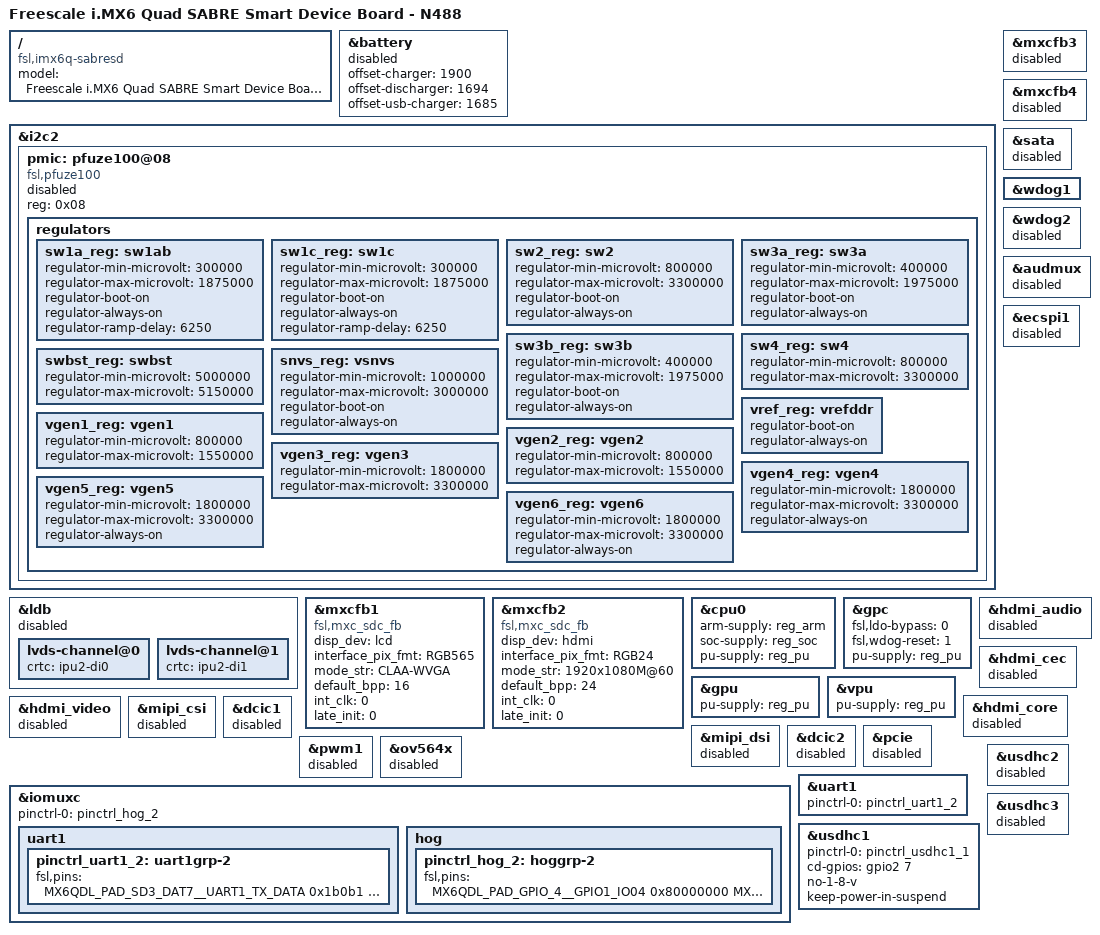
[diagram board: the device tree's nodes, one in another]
/*
 * Copyright 2012 Freescale Semiconductor, Inc.
 * Copyright 2011 Linaro Ltd.
 *
 * The code contained herein is licensed under the GNU General Public
 * License. You may obtain a copy of the GNU General Public License
 * Version 2 or later at the following locations:
 *
 * http://www.opensource.org/licenses/gpl-license.html
 * http://www.gnu.org/copyleft/gpl.html
 */

/dts-v1/;

#include "imx6q.dtsi"
#include "imx6qdl-sabresd.dtsi"

/ {
	model = "Freescale i.MX6 Quad SABRE Smart Device Board - N488";
	compatible = "fsl,imx6q-sabresd", "fsl,imx6q";
};

&battery {
	status = "disabled";
	offset-charger = <1900>;
	offset-discharger = <1694>;
	offset-usb-charger = <1685>;
};

&i2c2 {
	pmic: pfuze100@08 {
		status = "disabled";
		compatible = "fsl,pfuze100";
		reg = <0x08>;

		regulators {
			sw1a_reg: sw1ab {
				regulator-min-microvolt = <300000>;
				regulator-max-microvolt = <1875000>;
				regulator-boot-on;
				regulator-always-on;
				regulator-ramp-delay = <6250>;
			};

			sw1c_reg: sw1c {
				regulator-min-microvolt = <300000>;
				regulator-max-microvolt = <1875000>;
				regulator-boot-on;
				regulator-always-on;
				regulator-ramp-delay = <6250>;
			};

			sw2_reg: sw2 {
				regulator-min-microvolt = <800000>;
				regulator-max-microvolt = <3300000>;
				regulator-boot-on;
				regulator-always-on;
			};

			sw3a_reg: sw3a {
				regulator-min-microvolt = <400000>;
				regulator-max-microvolt = <1975000>;
				regulator-boot-on;
				regulator-always-on;
			};

			sw3b_reg: sw3b {
				regulator-min-microvolt = <400000>;
				regulator-max-microvolt = <1975000>;
				regulator-boot-on;
				regulator-always-on;
			};

			sw4_reg: sw4 {
				regulator-min-microvolt = <800000>;
				regulator-max-microvolt = <3300000>;
			};

			swbst_reg: swbst {
				regulator-min-microvolt = <5000000>;
				regulator-max-microvolt = <5150000>;
			};

			snvs_reg: vsnvs {
				regulator-min-microvolt = <1000000>;
				regulator-max-microvolt = <3000000>;
				regulator-boot-on;
				regulator-always-on;
			};

			vref_reg: vrefddr {
				regulator-boot-on;
				regulator-always-on;
			};

			vgen1_reg: vgen1 {
				regulator-min-microvolt = <800000>;
				regulator-max-microvolt = <1550000>;
			};

			vgen2_reg: vgen2 {
				regulator-min-microvolt = <800000>;
				regulator-max-microvolt = <1550000>;
			};

			vgen3_reg: vgen3 {
				regulator-min-microvolt = <1800000>;
				regulator-max-microvolt = <3300000>;
			};

			vgen4_reg: vgen4 {
				regulator-min-microvolt = <1800000>;
				regulator-max-microvolt = <3300000>;
				regulator-always-on;
			};

			vgen5_reg: vgen5 {
				regulator-min-microvolt = <1800000>;
				regulator-max-microvolt = <3300000>;
				regulator-always-on;
			};

			vgen6_reg: vgen6 {
				regulator-min-microvolt = <1800000>;
				regulator-max-microvolt = <3300000>;
				regulator-always-on;
			};
		};
	};
};

&ldb {
	status = "disabled";
	lvds-channel@0 {
		crtc = "ipu2-di0";
	};

	lvds-channel@1 {
		crtc = "ipu2-di1";
	};
};

/* use lcd panel as fb1 out */
&mxcfb1 {
	compatible = "fsl,mxc_sdc_fb";
	disp_dev = "lcd";
	interface_pix_fmt = "RGB565";
	mode_str ="CLAA-WVGA";
	default_bpp = <16>;
	int_clk = <0>;
	late_init = <0>;
	status = "okay";
};

/* use hdmi as fb2 out */
&mxcfb2 {
	compatible = "fsl,mxc_sdc_fb";
	disp_dev = "hdmi";
	interface_pix_fmt = "RGB24";
	mode_str ="1920x1080M@60";
	default_bpp = <24>;
	int_clk = <0>;
	late_init = <0>;
	status = "okay";
};

/* disable fb3 for now */
&mxcfb3 {
	status = "disabled";
};

/* disable fb4 for now */
&mxcfb4 {
	status = "disabled";
};

/* disable sata for now */
&sata {
	status = "disabled";
};



&cpu0 {
	arm-supply = <&reg_arm>;
	soc-supply = <&reg_soc>;
	pu-supply = <&reg_pu>; /* use pu_dummy if VDDSOC share with VDDPU */
};

&gpc {
	fsl,ldo-bypass = <0>; /* use ldo-bypass, u-boot will check it and configure */
	fsl,wdog-reset = <1>; /* watchdog select of reset source */
	pu-supply = <&reg_pu>; /* ldo-bypass:use pu_dummy if VDDSOC share with VDDPU */
};

&gpu {
	pu-supply = <&reg_pu>; /* ldo-bypass:use pu_dummy if VDDSOC share with VDDPU */
};

&vpu {
	pu-supply = <&reg_pu>; /* ldo-bypass:use pu_dummy if VDDSOC share with VDDPU */
};

&wdog1 {
	status = "okay";
};

&wdog2 {
	status = "disabled";
};


/*
 * modify for n488. +++
 */

/*
&backlight {
	status = "disabled";
};

&gpio-keys {
	status = "disabled";
};

&leds {
	status = "disabled";
};

&sound-hdmi {
	status = "disabled";
};

&sound {
	status = "disabled";
};
*/

&audmux {
	status = "disabled";
};

&ecspi1 {
	status = "disabled";
};

&hdmi_audio {
	status = "disabled";
};

&hdmi_cec {
	status = "disabled";
};

&hdmi_core {
	status = "disabled";
};

&hdmi_video {
	status = "disabled";
};

&mipi_csi {
	status = "disabled";
};

&mipi_dsi {
	status = "disabled";
};

&dcic1 {
	status = "disabled";
};

&dcic2 {
	status = "disabled";
};

&pcie {
	status = "disabled";
};

&pwm1 {
	status = "disabled";
};

&ov564x {
	status = "disabled";
};

&iomuxc {
	uart1 {
		pinctrl_uart1_2: uart1grp-2 {
			fsl,pins = <
				MX6QDL_PAD_SD3_DAT7__UART1_TX_DATA 0x1b0b1
				MX6QDL_PAD_SD3_DAT6__UART1_RX_DATA 0x1b0b1
			>;
		};
	};
};

&uart1 {
	pinctrl-names = "default";
	pinctrl-0 = <&pinctrl_uart1_2>;
	status = "okay";
};

&iomuxc {
	pinctrl-names = "default";
	pinctrl-0 = <&pinctrl_hog_2>;

	hog {
		pinctrl_hog_2: hoggrp-2 {
			fsl,pins = <
				MX6QDL_PAD_GPIO_4__GPIO1_IO04   0x80000000
				MX6QDL_PAD_GPIO_5__GPIO1_IO05   0x80000000
				MX6QDL_PAD_NANDF_D0__GPIO2_IO00 0x80000000
				MX6QDL_PAD_NANDF_D1__GPIO2_IO01 0x80000000
				MX6QDL_PAD_NANDF_D2__GPIO2_IO02 0x80000000
				MX6QDL_PAD_NANDF_D3__GPIO2_IO03 0x80000000
				MX6QDL_PAD_NANDF_ALE__GPIO6_IO08 0x80000000
				MX6QDL_PAD_NANDF_CLE__GPIO6_IO07 0x80000000
				MX6QDL_PAD_GPIO_0__CCM_CLKO1    0x130b0
				MX6QDL_PAD_NANDF_CS2__GPIO6_IO15 0x80000000
				MX6QDL_PAD_NANDF_CS3__GPIO6_IO16 0x80000000
				MX6QDL_PAD_EIM_D26__GPIO3_IO26 0x80000000
				MX6QDL_PAD_EIM_CS1__GPIO2_IO24 0x80000000
				MX6QDL_PAD_ENET_RXD0__GPIO1_IO27 0x80000000
				MX6QDL_PAD_EIM_A25__GPIO5_IO02 0x80000000
				MX6QDL_PAD_EIM_D23__GPIO3_IO23 0x80000000
				MX6QDL_PAD_ENET_TXD1__GPIO1_IO29 0x80000000
				MX6QDL_PAD_EIM_D22__GPIO3_IO22  0x80000000
				MX6QDL_PAD_NANDF_CS0__GPIO6_IO11 0x80000000
				MX6QDL_PAD_NANDF_CS1__GPIO6_IO14 0x80000000
				MX6QDL_PAD_EIM_EB3__GPIO2_IO31 0x80000000
				MX6QDL_PAD_EIM_D16__GPIO3_IO16 0x80000000
				MX6QDL_PAD_EIM_DA9__GPIO3_IO09 0x80000000
				MX6QDL_PAD_GPIO_4__GPIO1_IO04 0x80000000
				MX6QDL_PAD_GPIO_5__GPIO1_IO05 0x80000000
				MX6QDL_PAD_EIM_D29__GPIO3_IO29 0x80000000
				///MX6QDL_PAD_SD3_RST__GPIO7_IO08 0x80000000
				MX6QDL_PAD_GPIO_9__GPIO1_IO09 0x80000000
				MX6QDL_PAD_GPIO_1__WDOG2_B 0x80000000
				MX6QDL_PAD_GPIO_2__GPIO1_IO02 0x80000000
				///MX6QDL_PAD_SD1_CMD__GPIO1_IO18 0x80000000
			>;
		};
	};

};

&usdhc1 {
	pinctrl-names = "default";
	pinctrl-0 = <&pinctrl_usdhc1_1>;
	cd-gpios = <&gpio2 7 0>;
	no-1-8-v;
	keep-power-in-suspend;
	status = "okay";
};

&usdhc2 {
	status = "disabled";
};

&usdhc3 {
	status = "disabled";
};


/*
 * modify for n488. ---
 */


